# MCXA133 register map
Vendor: nxp.com; File version: 1.0
CPU: CM33 r2p0, little endian, no MPU, no FPU, VTOR, 3 interrupt priority bits
Registers are 32-bit, read-write, reset 0x0 unless marked. A register's access mark holds for its fields unless they carry their own. Offsets are from the block's base; [hi:lo] are bit positions; {n}, {i} and the like mark numbered series; 'fields as' and 'values as' point back to an identical list.

## FLEXPWM0 — PWM
Base 0x400A9000
{0x0+0x60*i} SM{i}CNT 16-bit ro (i=0..2) — Counter Register
  [15:0] CNT — Counter Register Bits
{0x2+0x60*i} SM{i}INIT 16-bit (i=0..2) — Initial Count Register
  [15:0] INIT — Initial Count Register Bits
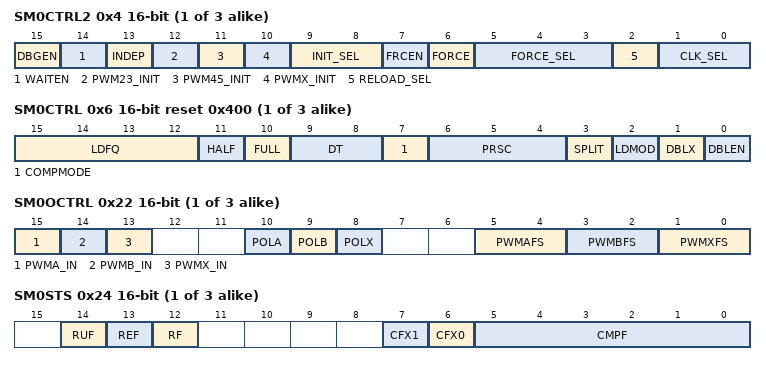
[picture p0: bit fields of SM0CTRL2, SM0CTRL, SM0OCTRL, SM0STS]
{0x4+0x60*i} SM{i}CTRL2 16-bit (i=0..2) — Control 2 Register
  [15] DBGEN — Debug Enable
  [14] WAITEN — Sleep Enable
  [13] INDEP — Independent or Complementary Pair Operation
    0=COMPLEMENTARY (PWM_A and PWM_B form a complementary PWM pair.); 1=INDEPENDENT (PWM_A and PWM_B outputs are independent PWMs.)
  [12] PWM23_INIT — PWM23 Initial Value
  [11] PWM45_INIT — PWM45 Initial Value
  [10] PWMX_INIT — PWM_X Initial Value
  [9:8] INIT_SEL — Initialization Control Select
    0=PWM_X (Local sync (PWM_X) causes initialization.); 1=MASTER_RELOAD (Master reload from submodule 0 causes initialization. This setting should not be used in submodule 0 as it forces the INIT signal to logic 0. The submodule counter will only re-initialize when a master reload occurs.); 2=MASTER_SYNC (Master sync from submodule 0 causes initialization. This setting should not be used in submodule 0 as it forces the INIT signal to logic 0.); 3=EXT_SYNC (EXT_SYNC causes initialization.)
  [7] FRCEN — Force Enable
    0=DISABLED (Initialization from a FORCE_OUT is disabled.); 1=ENABLED (Initialization from a FORCE_OUT is enabled.)
  [6] FORCE — Force Initialization
  [5:3] FORCE_SEL — Force Select
    0=LOCAL (The local force signal, CTRL2[FORCE], from this submodule is used to force updates.); 1=MASTER (The master force signal from submodule 0 is used to force updates. This setting should not be used in submodule 0 as it holds the FORCE OUTPUT signal to logic 0.); 2=LOCAL_RELOAD (The local reload signal from this submodule is used to force updates without regard to the state of LDOK.); 3=MASTER_RELOAD (The master reload signal from submodule0 is used to force updates if LDOK is set. This setting should not be used in submodule0 as it holds the FORCE OUTPUT signal to logic 0.); 4=LOCAL_SYNC (The local sync signal from this submodule is used to force updates.); 5=MASTER_SYNC (The master sync signal from submodule0 is used to force updates. This setting should not be used in submodule0 as it holds the FORCE OUTPUT signal to logic 0.); 6=EXT_FORCE (The external force signal, EXT_FORCE, from outside the PWM module causes updates.); 7=EXT_SYNC (The external sync signal, EXT_SYNC, from outside the PWM module causes updates.)
  [2] RELOAD_SEL — Reload Source Select
    0=LOCAL (The local RELOAD signal is used to reload registers.); 1=MASTER (The master RELOAD signal (from submodule 0) is used to reload registers. This setting should not be used in submodule 0 as it forces the RELOAD signal to logic 0.)
  [1:0] CLK_SEL — Clock Source Select
    0=IPBUS (The IPBus clock is used as the clock for the local prescaler and counter.); 1=EXT_CLK (EXT_CLK is used as the clock for the local prescaler and counter.); 2=AUX_CLK (Submodule 0's clock (AUX_CLK) is used as the source clock for the local prescaler and counter. This setting should not be used in submodule 0 as it forces the clock to logic 0.)
{0x6+0x60*i} SM{i}CTRL 16-bit reset 0x400 (i=0..2) — Control Register
  [15:12] LDFQ — Load Frequency
    0=EVERYPWM (Every PWM opportunity); {v}=EVERY{v+1}PWM (Every {v+1} PWM opportunities) (v=1..15)
  [11] HALF — Half Cycle Reload
    0=DISABLED (Half-cycle reloads disabled.); 1=ENABLED (Half-cycle reloads enabled.)
  [10] FULL — Full Cycle Reload
    0=DISABLED (Full-cycle reloads disabled.); 1=ENABLED (Full-cycle reloads enabled.)
  [9:8] DT ro — Deadtime
  [7] COMPMODE — Compare Mode
    0=EQUAL_TO (The VAL* registers and the PWM counter are compared using an "equal to" method. This means that PWM edges are only produced when the counter is equal to one of the VAL* register values. This implies that a PWM_A output that is high at the end of a period maintains this state until a match with VAL3 clears the output in the following period.); 1=EQUAL_TO_OR_GREATER_THAN (The VAL* registers and the PWM counter are compared using an "equal to or greater than" method. This means that PWM edges are produced when the counter is equal to or greater than one of the VAL* register values. This implies that a PWM_A output that is high at the end of a period could go low at the start of the next period if the starting counter value is greater than (but not necessarily equal to) the new VAL3 value.)
  [6:4] PRSC — Prescaler
    0=ONE (Prescaler 1); 1=TWO (Prescaler 2); 2=FOUR (Prescaler 4); 3=EIGHT (Prescaler 8); 4=SIXTEEN (Prescaler 16); 5=THIRTYTWO (Prescaler 32); 6=SIXTYFOUR (Prescaler 64); 7=HUNDREDTWENTYEIGHT (Prescaler 128)
  [3] SPLIT — Split the DBLPWM signal to PWM_A and PWM_B
    0=DISABLED (DBLPWM is not split. PWM_A and PWM_B each have double pulses.); 1=ENABLED (DBLPWM is split to PWM_A and PWM_B.)
  [2] LDMOD — Load Mode Select
    0=NEXT_PWM_RELOAD (Buffered registers of this submodule are loaded and take effect at the next PWM reload if MCTRL[LDOK] is set.); 1=MTCTRL_LDOK_SET (Buffered registers of this submodule are loaded and take effect immediately upon MCTRL[LDOK] being set. In this case, it is not necessary to set CTRL[FULL] or CTRL[HALF].)
  [1] DBLX — PWM_X Double Switching Enable
    0=DISABLED (PWM_X double pulse disabled.); 1=ENABLED (PWM_X double pulse enabled.)
  [0] DBLEN — Double Switching Enable
    0=DISABLED (Double switching disabled.); 1=ENABLED (Double switching enabled.)
{0xA+4i} SM0VAL{i} 16-bit (i=0..5) — Value Register {i}
  [15:0] VAL{i} — Value {i}
{0x22+0x60*i} SM{i}OCTRL 16-bit (i=0..2) — Output Control Register
  [15] PWMA_IN ro — PWM_A Input
  [14] PWMB_IN ro — PWM_B Input
  [13] PWMX_IN ro — PWM_X Input
  [10] POLA — PWM_A Output Polarity
    0=NOT_INVERTED (PWM_A output not inverted. A high level on the PWM_A pin represents the "on" or "active" state.); 1=INVERTED (PWM_A output inverted. A low level on the PWM_A pin represents the "on" or "active" state.)
  [9] POLB — PWM_B Output Polarity
    0=NOT_INVERTED (PWM_B output not inverted. A high level on the PWM_B pin represents the "on" or "active" state.); 1=INVERTED (PWM_B output inverted. A low level on the PWM_B pin represents the "on" or "active" state.)
  [8] POLX — PWM_X Output Polarity
    0=NOT_INVERTED (PWM_X output not inverted. A high level on the PWM_X pin represents the "on" or "active" state.); 1=INVERTED (PWM_X output inverted. A low level on the PWM_X pin represents the "on" or "active" state.)
  [5:4] PWMAFS — PWM_A Fault State
    0=LOGIC_0 (Output is forced to logic 0 state prior to consideration of output polarity control.); 1=LOGIC_1 (Output is forced to logic 1 state prior to consideration of output polarity control.); 2=TRISTATED_2 (Output is put in a high-impedance state.); 3=TRISTATED_3 (Output is put in a high-impedance state.)
  [3:2] PWMBFS — PWM_B Fault State
    values as PWMAFS
  [1:0] PWMXFS — PWM_X Fault State
    values as PWMAFS
{0x24+0x60*i} SM{i}STS 16-bit (i=0..2) — Status Register
  [14] RUF ro — Registers Updated Flag
    0=NO_FLAG (No register update has occurred since last reload.); 1=FLAG (At least one of the double buffered registers has been updated since the last reload.)
  [13] REF write-1-clears — Reload Error Flag
    0=NO_FLAG (No reload error occurred.); 1=FLAG (Reload signal occurred with non-coherent data and MCTRL[LDOK] = 0.)
  [12] RF write-1-clears — Reload Flag
    0=NO_FLAG (No new reload cycle since last STS[RF] clearing); 1=FLAG (New reload cycle since last STS[RF] clearing)
  [7] CFX1 write-1-clears — Capture Flag X1
  [6] CFX0 write-1-clears — Capture Flag X0
  [5:0] CMPF write-1-clears — Compare Flags
    0=NO_EVENT (No compare event has occurred for a particular VALx value.); 1=EVENT (A compare event has occurred for a particular VALx value.)
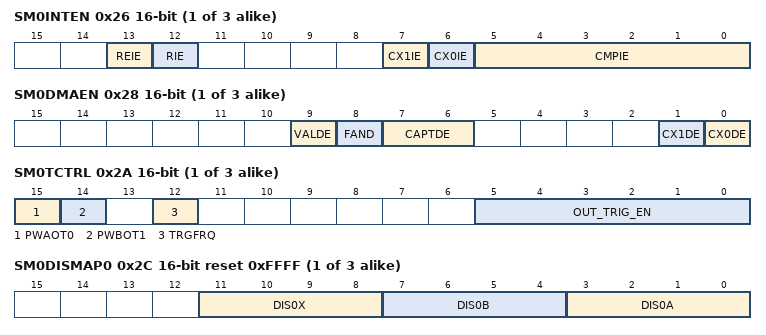
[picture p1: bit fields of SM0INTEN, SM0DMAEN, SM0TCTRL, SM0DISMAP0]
{0x26+0x60*i} SM{i}INTEN 16-bit (i=0..2) — Interrupt Enable Register
  [13] REIE — Reload Error Interrupt Enable
    0=DISABLED (STS[REF] CPU interrupt requests disabled); 1=ENABLED (STS[REF] CPU interrupt requests enabled)
  [12] RIE — Reload Interrupt Enable
    0=DISABLED (STS[RF] CPU interrupt requests disabled); 1=ENABLED (STS[RF] CPU interrupt requests enabled)
  [7] CX1IE — Capture X 1 Interrupt Enable
    0=DISABLED (Interrupt request disabled for STS[CFX1].); 1=ENABLED (Interrupt request enabled for STS[CFX1].)
  [6] CX0IE — Capture X 0 Interrupt Enable
    0=DISABLED (Interrupt request disabled for STS[CFX0].); 1=ENABLED (Interrupt request enabled for STS[CFX0].)
  [5:0] CMPIE — Compare Interrupt Enables
    0=DISABLED (The corresponding STS[CMPF] bit will not cause an interrupt request.); 1=ENABLED (The corresponding STS[CMPF] bit will cause an interrupt request.)
{0x28+0x60*i} SM{i}DMAEN 16-bit (i=0..2) — DMA Enable Register
  [9] VALDE — Value Registers DMA Enable
    0=DISABLED (DMA write requests disabled); 1=ENABLED
  [8] FAND — FIFO Watermark AND Control
    0=OR (Selected FIFO watermarks are OR'ed together.); 1=AND (Selected FIFO watermarks are AND'ed together.)
  [7:6] CAPTDE — Capture DMA Enable Source Select
    0=DISABLED (Read DMA requests disabled.); 1=EXCEEDFIFO (Exceeding a FIFO watermark sets the DMA read request. This requires at least one of DMAEN[CA1DE], DMAEN[CA0DE], DMAEN[CB1DE], DMAEN[CB0DE], DMAEN[CX1DE], or DMAEN[CX0DE] to be set to determine which watermark(s) the DMA request is sensitive.); 2=LOCAL_SYNC (A local synchronization (VAL1 matches counter) sets the read DMA request.); 3=LOCAL_RELOAD (A local reload (STS[RF] being set) sets the read DMA request.)
  [1] CX1DE — Capture X1 FIFO DMA Enable
  [0] CX0DE — Capture X0 FIFO DMA Enable
{0x2A+0x60*i} SM{i}TCTRL 16-bit (i=0..2) — Output Trigger Control Register
  [15] PWAOT0 — Mux Output Trigger 0 Source Select
    0=PWM_OUT_TRIG0_SIGNAL (Route the PWM_OUT_TRIG0 signal to PWM_MUX_TRIG0 port.); 1=PWMA_OUTPUT (Route the PWM_A output to the PWM_MUX_TRIG0 port.)
  [14] PWBOT1 — Mux Output Trigger 1 Source Select
    0=PWM_OUT_TRIG1_SIGNAL (Route the PWM_OUT_TRIG1 signal to PWM_MUX_TRIG1 port.); 1=PWMB_OUTPUT (Route the PWM_B output to the PWM_MUX_TRIG1 port.)
  [12] TRGFRQ — Trigger Frequency
    0=EVERYPWM (Trigger outputs are generated during every PWM period even if the PWM is not reloaded every period due to CTRL[LDFQ] being non-zero.); 1=FINALPWM (Trigger outputs are generated only during the final PWM period prior to a reload opportunity when the PWM is not reloaded every period due to CTRL[LDFQ] being non-zero.)
  [5:0] OUT_TRIG_EN — Output Trigger Enables
    0bxxxxx1=PWM_OUT_TRIG0 will set when the counter value matches the VAL0 value; 0bxxxx1x=PWM_OUT_TRIG1 will set when the counter value matches the VAL1 value; 0bxxx1xx=PWM_OUT_TRIG0 will set when the counter value matches the VAL2 value; 0bxx1xxx=PWM_OUT_TRIG1 will set when the counter value matches the VAL3 value; 0bx1xxxx=PWM_OUT_TRIG0 will set when the counter value matches the VAL4 value; 0b1xxxxx=PWM_OUT_TRIG1 will set when the counter value matches the VAL5 value
{0x2C+0x60*i} SM{i}DISMAP0 16-bit reset 0xFFFF (i=0..2) — Fault Disable Mapping Register 0
  [11:8] DIS0X — PWM_X Fault Disable Mask 0
  [7:4] DIS0B — PWM_B Fault Disable Mask 0
  [3:0] DIS0A — PWM_A Fault Disable Mask 0
{0x30+0x60*i} SM{i}DTCNT0 16-bit reset 0x7FF (i=0..2) — Deadtime Count Register 0
  [10:0] DTCNT0
{0x32+0x60*i} SM{i}DTCNT1 16-bit reset 0x7FF (i=0..2) — Deadtime Count Register 1
  [10:0] DTCNT1
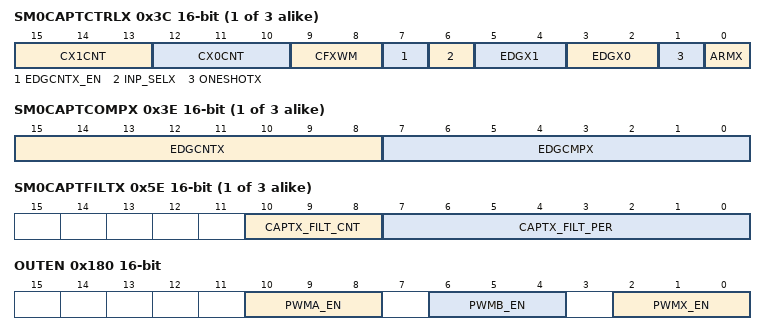
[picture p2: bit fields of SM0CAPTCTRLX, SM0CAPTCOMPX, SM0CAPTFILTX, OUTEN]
{0x3C+0x60*i} SM{i}CAPTCTRLX 16-bit (i=0..2) — Capture Control X Register
  [15:13] CX1CNT ro — Capture X1 FIFO Word Count
  [12:10] CX0CNT ro — Capture X0 FIFO Word Count
  [9:8] CFXWM — Capture X FIFOs Water Mark
  [7] EDGCNTX_EN — Edge Counter X Enable
    0=DISABLED (Edge counter disabled and held in reset); 1=ENABLED (Edge counter enabled)
  [6] INP_SELX — Input Select X
    0=PWM_X (Raw PWM_X input signal selected as source.); 1=EDGE_COUNTER
  [5:4] EDGX1 — Edge X 1
    0=DISABLED; 1=FALLING_EDGE (Capture falling edges); 2=RISING_EDGE (Capture rising edges); 3=ANY_EDGE (Capture any edge)
  [3:2] EDGX0 — Edge X 0
    values as EDGX1
  [1] ONESHOTX — One Shot Mode Aux
    0=FREE_RUNNING; 1=ONE_SHOT
  [0] ARMX
    0=DISABLED (Input capture operation is disabled.); 1=ENABLED (Input capture operation as specified by CAPTCTRLX[EDGXx] is enabled.)
{0x3E+0x60*i} SM{i}CAPTCOMPX 16-bit (i=0..2) — Capture Compare X Register
  [15:8] EDGCNTX ro — Edge Counter X
  [7:0] EDGCMPX — Edge Compare X
{0x40+0x60*i} SM{i}CVAL0 16-bit ro (i=0..2) — Capture Value 0 Register
  [15:0] CAPTVAL0 — Capture Value 0
{0x42+0x60*i} SM{i}CVAL0CYC 16-bit ro (i=0..2) — Capture Value 0 Cycle Register
  [3:0] CVAL0CYC — Capture Value 0 Cycle
{0x44+0x60*i} SM{i}CVAL1 16-bit ro (i=0..2) — Capture Value 1 Register
  [15:0] CAPTVAL1 — Capture Value 1
{0x46+0x60*i} SM{i}CVAL1CYC 16-bit ro (i=0..2) — Capture Value 1 Cycle Register
  [3:0] CVAL1CYC — Capture Value 1 Cycle
{0x5E+0x60*i} SM{i}CAPTFILTX 16-bit (i=0..2) — Capture PWM_X Input Filter Register
  [10:8] CAPTX_FILT_CNT — Input Capture Filter Count
  [7:0] CAPTX_FILT_PER — Input Capture Filter Period
{0x6A+4i} SM1VAL{i} 16-bit (i=0..5) — Value Register {i}
  [15:0] VAL{i} — Value {i}
0xB8 SM1PHASEDLY 16-bit — Phase Delay Register
  [15:0] PHASEDLY — Initial Count Register Bits
{0xCA+4i} SM2VAL{i} 16-bit (i=0..5) — Value Register {i}
  [15:0] VAL{i} — Value {i}
0x118 SM2PHASEDLY 16-bit — Phase Delay Register
  [15:0] PHASEDLY — Initial Count Register Bits
0x180 OUTEN 16-bit — Output Enable Register
  [10:8] PWMA_EN — PWM_A Output Enables
  [6:4] PWMB_EN — PWM_B Output Enables
  [2:0] PWMX_EN — PWM_X Output Enables
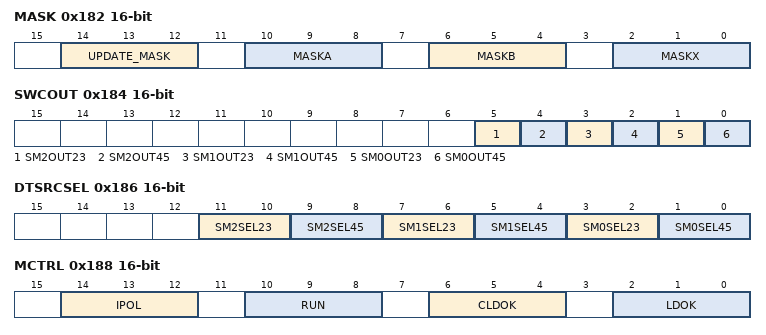
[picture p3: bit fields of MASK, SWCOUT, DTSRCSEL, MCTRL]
0x182 MASK 16-bit
  [14:12] UPDATE_MASK wo — Update Mask Bits Immediately
  [10:8] MASKA — PWM_A Masks
  [6:4] MASKB — PWM_B Masks
  [2:0] MASKX — PWM_X Masks
0x184 SWCOUT 16-bit — Software Controlled Output Register
  [5] SM2OUT23 — Submodule 2 Software Controlled Output 23
    0=LOGIC_0 (A logic 0 is supplied to the deadtime generator of submodule 2 instead of PWM23.); 1=LOGIC_1 (A logic 1 is supplied to the deadtime generator of submodule 2 instead of PWM23.)
  [4] SM2OUT45 — Submodule 2 Software Controlled Output 45
    0=LOGIC_0 (A logic 0 is supplied to the deadtime generator of submodule 2 instead of PWM45.); 1=LOGIC_1 (A logic 1 is supplied to the deadtime generator of submodule 2 instead of PWM45.)
  [3] SM1OUT23 — Submodule 1 Software Controlled Output 23
    0=LOGIC_0 (A logic 0 is supplied to the deadtime generator of submodule 1 instead of PWM23.); 1=LOGIC_1 (A logic 1 is supplied to the deadtime generator of submodule 1 instead of PWM23.)
  [2] SM1OUT45 — Submodule 1 Software Controlled Output 45
    0=LOGIC_0 (A logic 0 is supplied to the deadtime generator of submodule 1 instead of PWM45.); 1=LOGIC_1 (A logic 1 is supplied to the deadtime generator of submodule 1 instead of PWM45.)
  [1] SM0OUT23 — Submodule 0 Software Controlled Output 23
    0=LOGIC_0 (A logic 0 is supplied to the deadtime generator of submodule 0 instead of PWM23.); 1=LOGIC_1 (A logic 1 is supplied to the deadtime generator of submodule 0 instead of PWM23.)
  [0] SM0OUT45 — Submodule 0 Software Controlled Output 45
    0=LOGIC_0 (A logic 0 is supplied to the deadtime generator of submodule 0 instead of PWM45.); 1=LOGIC_1 (A logic 1 is supplied to the deadtime generator of submodule 0 instead of PWM45.)
0x186 DTSRCSEL 16-bit — PWM Source Select Register
  [11:10] SM2SEL23 — Submodule 2 PWM23 Control Select
    0=SM2PWM23 (Generated SM2PWM23 signal used by the deadtime logic.); 1=INVERTED_SM2PWM23 (Inverted generated SM2PWM23 signal used by the deadtime logic.); 2=SM2OUT23 (SWCOUT[SM2OUT23] used by the deadtime logic.); 3=PWM2_EXTA (PWM2_EXTA signal used by the deadtime logic.)
  [9:8] SM2SEL45 — Submodule 2 PWM45 Control Select
    0=SM2PWM45 (Generated SM2PWM45 signal used by the deadtime logic.); 1=INVERTED_SM2PWM45 (Inverted generated SM2PWM45 signal used by the deadtime logic.); 2=SM2OUT45 (SWCOUT[SM2OUT45] used by the deadtime logic.)
  [7:6] SM1SEL23 — Submodule 1 PWM23 Control Select
    0=SM1PWM23 (Generated SM1PWM23 signal used by the deadtime logic.); 1=INVERTED_SM1PWM23 (Inverted generated SM1PWM23 signal used by the deadtime logic.); 2=SM1OUT23 (SWCOUT[SM1OUT23] used by the deadtime logic.); 3=PWM1_EXTA (PWM1_EXTA signal used by the deadtime logic.)
  [5:4] SM1SEL45 — Submodule 1 PWM45 Control Select
    0=SM1PWM45 (Generated SM1PWM45 signal used by the deadtime logic.); 1=INVERTED_SM1PWM45 (Inverted generated SM1PWM45 signal used by the deadtime logic.); 2=SM1OUT45 (SWCOUT[SM1OUT45] used by the deadtime logic.)
  [3:2] SM0SEL23 — Submodule 0 PWM23 Control Select
    0=SM0PWM23 (Generated SM0PWM23 signal used by the deadtime logic.); 1=INVERTED_SM0PWM23 (Inverted generated SM0PWM23 signal used by the deadtime logic.); 2=SM0OUT23 (SWCOUT[SM0OUT23] used by the deadtime logic.); 3=PWM0_EXTA (PWM0_EXTA signal used by the deadtime logic.)
  [1:0] SM0SEL45 — Submodule 0 PWM45 Control Select
    0=SM0PWM45 (Generated SM0PWM45 signal used by the deadtime logic.); 1=INVERTED_SM0PWM45 (Inverted generated SM0PWM45 signal used by the deadtime logic.); 2=SM0OUT45 (SWCOUT[SM0OUT45] used by the deadtime logic.)
0x188 MCTRL 16-bit — Master Control Register
  [14:12] IPOL — Current Polarity
    0=PWM23 (PWM23 is used to generate complementary PWM pair in the corresponding submodule.); 1=PWM45 (PWM45 is used to generate complementary PWM pair in the corresponding submodule.)
  [10:8] RUN
    0=DISABLED (PWM counter is stopped, but PWM outputs hold the current state.); 1=ENABLED (PWM counter is started in the corresponding submodule.)
  [6:4] CLDOK — Clear Load Okay
  [2:0] LDOK — Load Okay
    0=DISABLED (Do not load new values.); 1=ENABLED (Load prescaler, modulus, and PWM values of the corresponding submodule.)
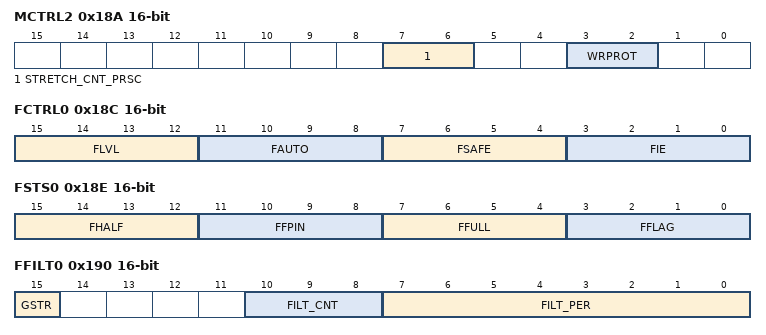
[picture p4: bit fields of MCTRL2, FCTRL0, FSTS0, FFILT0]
0x18A MCTRL2 16-bit — Master Control 2 Register
  [7:6] STRETCH_CNT_PRSC — Stretch IPBus clock count prescaler for mux0_trig/mux1_trig/out0_trig/out1_trig/pwma_trig/pwmb_trig
    0=DISABLED (Stretch count is zero, no stretch.); 1=ENABLED (Stretch mux0_trig/mux1_trig/out0_trig/out1_trig/pwma_trig/pwmb_trig for 2 IPBus clock period.); 2=DISABLED_LOCKED (Stretch mux0_trig/mux1_trig/out0_trig/out1_trig/pwma_trig/pwmb_trig for 4 IPBus clock period.); 3=ENABLED_LOCKED (Stretch mux0_trig/mux1_trig/out0_trig/out1_trig/pwma_trig/pwmb_trig for 8 IPBus clock period.)
  [3:2] WRPROT — Write protect
    0=DISABLED (Write protection off (default).); 1=ENABLED (Write protection on.); 2=DISABLED_LOCKED (Write protection off and locked until chip reset.); 3=ENABLED_LOCKED (Write protection on and locked until chip reset.)
0x18C FCTRL0 16-bit — Fault Control Register
  [15:12] FLVL — Fault Level
    0=LOGIC_0 (A logic 0 on the fault input indicates a fault condition.); 1=LOGIC_1 (A logic 1 on the fault input indicates a fault condition.)
  [11:8] FAUTO — Automatic Fault Clearing
    0=MANUAL (Manual fault clearing. PWM outputs disabled by this fault are not enabled until FSTS[FFLAGx] is clear at the start of a half cycle or full cycle depending on the states of FSTS[FHALF] and FSTS[FFULL]. If neither FFULL nor FHALF is set, then the fault condition cannot be cleared. This is further controlled by FCTRL[FSAFE].); 1=AUTOMATIC (Automatic fault clearing. PWM outputs disabled by this fault are enabled when FSTS[FFPINx] is clear at the start of a half cycle or full cycle depending on the states of FSTS[FHALF] and FSTS[FFULL] without regard to the state of FSTS[FFLAGx]. If neither FFULL nor FHALF is set, then the fault condition cannot be cleared.)
  [7:4] FSAFE — Fault Safety Mode
    0=NORMAL (Normal mode. PWM outputs disabled by this fault are not enabled until FSTS[FFLAGx] is clear at the start of a half cycle or full cycle depending on the states of FSTS[FHALF] and FSTS[FFULL] without regard to the state of FSTS[FFPINx]. If neither FHALF nor FFULL is set, then the fault condition cannot be cleared. The PWM outputs disabled by this fault input will not be re-enabled until the actual FAULTx input signal de-asserts since the fault input will combinationally disable the PWM outputs (as programmed in DISMAPn).); 1=SAFE (Safe mode. PWM outputs disabled by this fault are not enabled until FSTS[FFLAGx] is clear and FSTS[FFPINx] is clear at the start of a half cycle or full cycle depending on the states of FSTS[FHALF] and FSTS[FFULL]. If neither FHLAF nor FFULL is set, then the fault condition cannot be cleared.)
  [3:0] FIE — Fault Interrupt Enables
    0=DISABLED (FAULTx CPU interrupt requests disabled.); 1=ENABLED (FAULTx CPU interrupt requests enabled.)
0x18E FSTS0 16-bit (reset mask 0xF0F0) — Fault Status Register
  [15:12] FHALF — Half Cycle Fault Recovery
    0=PWM_OUTPUTS_NOT_REENABLED (PWM outputs are not re-enabled at the start of a half cycle.); 1=PWM_OUTPUTS_REENABLED (PWM outputs are re-enabled at the start of a half cycle (as defined by VAL0).)
  [11:8] FFPIN ro — Filtered Fault Pins
  [7:4] FFULL — Full Cycle
    0=PWM_OUTPUTS_NOT_REENABLED (PWM outputs are not re-enabled at the start of a full cycle); 1=PWM_OUTPUTS_REENABLED (PWM outputs are re-enabled at the start of a full cycle)
  [3:0] FFLAG — Fault Flags
    0=NO_FLAG (No fault on the FAULTx pin.); 1=FLAG (Fault on the FAULTx pin.)
0x190 FFILT0 16-bit — Fault Filter Register
  [15] GSTR — Fault Glitch Stretch Enable
    0=DISABLED (Fault input glitch stretching is disabled.); 1=ENABLED (Input fault signals are stretched to at least 2 IPBus clock cycles.)
  [10:8] FILT_CNT — Fault Filter Count
  [7:0] FILT_PER — Fault Filter Period
0x192 FTST0 16-bit — Fault Test Register
  [0] FTEST — Fault Test
    0=NO_FAULT; 1=FAULT (Cause a simulated fault)
0x194 FCTRL20 16-bit — Fault Control 2 Register
  [3:0] NOCOMB — No Combinational Path From Fault Input To PWM Output
    0=ENABLED (There is a combinational link from the fault inputs to the PWM outputs. The fault inputs are combined with the filtered and latched fault signals to disable the PWM outputs.); 1=DISABLED (The direct combinational path from the fault inputs to the PWM outputs is disabled and the filtered and latched fault signals are used to disable the PWM outputs.)
